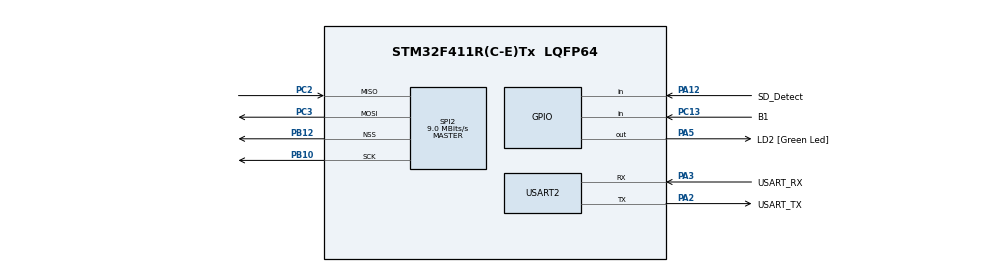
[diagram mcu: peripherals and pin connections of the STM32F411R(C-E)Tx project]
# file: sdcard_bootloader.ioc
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FATFS._CODE_PAGE=437
FATFS._FS_LOCK=0
FATFS._FS_MINIMIZE=0
FATFS._FS_READONLY=0
FATFS._MAX_SS=4096
FATFS._USE_FASTSEEK=0
FATFS._USE_LFN=1
FATFS._USE_MKFS=0
Mcu.Family=STM32F4
Mcu.Name=STM32F411R(C-E)Tx
Mcu.Package=LQFP64
NVIC.PriorityGroup=NVIC_PRIORITYGROUP_0
NVIC.USART2_IRQn=true\:0\:0\:false\:false\:true\:true\:true\:true
PA12.GPIO_Label=SD_Detect
PA12.Signal=GPIO_Input
PA13.GPIO_Label=TMS
PA13.Mode=Serial_Wire
PA13.Signal=SYS_JTMS-SWDIO
PA14.GPIO_Label=TCK
PA14.Mode=Serial_Wire
PA14.Signal=SYS_JTCK-SWCLK
PA2.GPIO_Label=USART_TX
PA2.Mode=Asynchronous
PA2.Signal=USART2_TX
PA3.GPIO_Label=USART_RX
PA3.Mode=Asynchronous
PA3.Signal=USART2_RX
PA5.GPIO_Label=LD2 [Green Led]
PA5.Signal=GPIO_Output
PB10.Mode=Full_Duplex_Master
PB10.Signal=SPI2_SCK
PB12.Mode=NSS_Signal_Hard_Output
PB12.Signal=SPI2_NSS
PB3.GPIO_Label=SWO
PB3.Signal=SYS_JTDO-SWO
PC13-ANTI_TAMP.GPIO_Label=B1
PC13-ANTI_TAMP.Signal=GPIO_Input
PC14-OSC32_IN.Mode=LSE-External-Oscillator
PC14-OSC32_IN.Signal=RCC_OSC32_IN
PC15-OSC32_OUT.Mode=LSE-External-Oscillator
PC15-OSC32_OUT.Signal=RCC_OSC32_OUT
PC2.Mode=Full_Duplex_Master
PC2.Signal=SPI2_MISO
PC3.Mode=Full_Duplex_Master
PC3.Signal=SPI2_MOSI
PC8.Signal=SDIO_D0
PD2.Signal=SDIO_CMD
PH0\ -\ OSC_IN.Mode=HSE-External-Clock-Source
PH0\ -\ OSC_IN.Signal=RCC_OSC_IN
PH1\ -\ OSC_OUT.Mode=HSE-External-Clock-Source
PH1\ -\ OSC_OUT.Signal=RCC_OSC_OUT
ProjectManager.HeapSize=0x200
ProjectManager.StackSize=0x400
ProjectManager.TargetToolchain=STM32CubeIDE
RCC.48MHZClocksFreq_Value=36000000
RCC.AHBFreq_Value=72000000
RCC.APB1CLKDivider=RCC_HCLK_DIV2
RCC.APB1Freq_Value=36000000
RCC.APB1TimFreq_Value=72000000
RCC.APB2Freq_Value=72000000
RCC.APB2TimFreq_Value=72000000
RCC.CortexFreq_Value=72000000
RCC.FLatency-AdvancedSettings=FLASH_LATENCY_2
RCC.HCLKFreq_Value=72000000
RCC.HSE_VALUE=8000000
RCC.HSI_VALUE=16000000
RCC.PLLM=8
RCC.PLLN=72
RCC.SYSCLKFreq_VALUE=72000000
RCC.SYSCLKSource=RCC_SYSCLKSOURCE_PLLCLK
RCC.VCOOutputFreq_Value=144000000
SPI2.BaudRatePrescaler=SPI_BAUDRATEPRESCALER_4
SPI2.CalculateBaudRate=9.0 MBits/s
SPI2.Direction=SPI_DIRECTION_2LINES
SPI2.Mode=SPI_MODE_MASTER
SPI2.VirtualNSS=VM_NSSHARD
SPI2.VirtualType=VM_MASTER
USART2.VirtualMode=VM_ASYNC
VP_FATFS_VS_Generic.Mode=User_defined
board=NUCLEO-F411RE

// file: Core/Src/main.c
/* USER CODE BEGIN Header */
/**
  ******************************************************************************
  * @file           : main.c
  * @brief          : Main program body
  ******************************************************************************
  * @attention
  *
  * Copyright (c) 2022 STMicroelectronics.
  * All rights reserved.
  *
  * This software is licensed under terms that can be found in the LICENSE file
  * in the root directory of this software component.
  * If no LICENSE file comes with this software, it is provided AS-IS.
  *
  ******************************************************************************
  */
/* USER CODE END Header */
#include "main.h"
#include "bootloader.h"

void SystemClock_Config(void);
static void MX_GPIO_Init(void);
static void MX_USART2_UART_Init(void);
static void MX_SPI2_Init(void);

int main(void)
{

  /* MCU Configuration--------------------------------------------------------*/

  /* Reset of all peripherals, Initializes the Flash interface and the Systick. */
  HAL_Init();

  /* Configure the system clock */
  SystemClock_Config();

  /* Initialize all configured peripherals */
  MX_GPIO_Init();
  MX_USART2_UART_Init();
  MX_FATFS_Init();
  MX_SPI2_Init();
  /* USER CODE BEGIN 2 */
  bootloader_mainloop();

  /* USER CODE END 2 */

  /* Infinite loop */
  while (1)
  {

  }
}

void SystemClock_Config(void)
{
  LL_FLASH_SetLatency(LL_FLASH_LATENCY_2);
  while(LL_FLASH_GetLatency()!= LL_FLASH_LATENCY_2)
  {
  }
  LL_PWR_SetRegulVoltageScaling(LL_PWR_REGU_VOLTAGE_SCALE1);
  LL_RCC_HSI_SetCalibTrimming(16);
  LL_RCC_HSI_Enable();

   /* Wait till HSI is ready */
  while(LL_RCC_HSI_IsReady() != 1)
  {

  }
  LL_RCC_PLL_ConfigDomain_SYS(LL_RCC_PLLSOURCE_HSI, LL_RCC_PLLM_DIV_8, 72, LL_RCC_PLLP_DIV_2);
  LL_RCC_PLL_Enable();

   /* Wait till PLL is ready */
  while(LL_RCC_PLL_IsReady() != 1)
  {

  }
  LL_RCC_SetAHBPrescaler(LL_RCC_SYSCLK_DIV_1);
  LL_RCC_SetAPB1Prescaler(LL_RCC_APB1_DIV_2);
  LL_RCC_SetAPB2Prescaler(LL_RCC_APB2_DIV_1);
  LL_RCC_SetSysClkSource(LL_RCC_SYS_CLKSOURCE_PLL);

   /* Wait till System clock is ready */
  while(LL_RCC_GetSysClkSource() != LL_RCC_SYS_CLKSOURCE_STATUS_PLL)
  {

  }
  LL_SetSystemCoreClock(72000000);

   /* Update the time base */
  if (HAL_InitTick (TICK_INT_PRIORITY) != HAL_OK)
  {
    Error_Handler();
  }
  LL_RCC_SetTIMPrescaler(LL_RCC_TIM_PRESCALER_TWICE);
}

static void MX_SPI2_Init(void)
{

  LL_SPI_InitTypeDef SPI_InitStruct = {0};

  LL_GPIO_InitTypeDef GPIO_InitStruct = {0};

  /* Peripheral clock enable */
  LL_APB1_GRP1_EnableClock(LL_APB1_GRP1_PERIPH_SPI2);

  LL_AHB1_GRP1_EnableClock(LL_AHB1_GRP1_PERIPH_GPIOC);
  LL_AHB1_GRP1_EnableClock(LL_AHB1_GRP1_PERIPH_GPIOB);
  /**SPI2 GPIO Configuration
  PC2   ------> SPI2_MISO
  PC3   ------> SPI2_MOSI
  PB10   ------> SPI2_SCK
  PB12   ------> SPI2_NSS
  */
  GPIO_InitStruct.Pin = LL_GPIO_PIN_2|LL_GPIO_PIN_3;
  GPIO_InitStruct.Mode = LL_GPIO_MODE_ALTERNATE;
  GPIO_InitStruct.Speed = LL_GPIO_SPEED_FREQ_VERY_HIGH;
  GPIO_InitStruct.OutputType = LL_GPIO_OUTPUT_PUSHPULL;
  GPIO_InitStruct.Pull = LL_GPIO_PULL_NO;
  GPIO_InitStruct.Alternate = LL_GPIO_AF_5;
  LL_GPIO_Init(GPIOC, &GPIO_InitStruct);

  GPIO_InitStruct.Pin = LL_GPIO_PIN_10|LL_GPIO_PIN_12;
  GPIO_InitStruct.Mode = LL_GPIO_MODE_ALTERNATE;
  GPIO_InitStruct.Speed = LL_GPIO_SPEED_FREQ_VERY_HIGH;
  GPIO_InitStruct.OutputType = LL_GPIO_OUTPUT_PUSHPULL;
  GPIO_InitStruct.Pull = LL_GPIO_PULL_NO;
  GPIO_InitStruct.Alternate = LL_GPIO_AF_5;
  LL_GPIO_Init(GPIOB, &GPIO_InitStruct);

  /* SPI2 parameter configuration*/
  SPI_InitStruct.TransferDirection = LL_SPI_FULL_DUPLEX;
  SPI_InitStruct.Mode = LL_SPI_MODE_MASTER;
  SPI_InitStruct.DataWidth = LL_SPI_DATAWIDTH_8BIT;
  SPI_InitStruct.ClockPolarity = LL_SPI_POLARITY_LOW;
  SPI_InitStruct.ClockPhase = LL_SPI_PHASE_1EDGE;
  SPI_InitStruct.NSS = LL_SPI_NSS_HARD_OUTPUT;
  SPI_InitStruct.BaudRate = LL_SPI_BAUDRATEPRESCALER_DIV4;
  SPI_InitStruct.BitOrder = LL_SPI_MSB_FIRST;
  SPI_InitStruct.CRCCalculation = LL_SPI_CRCCALCULATION_DISABLE;
  SPI_InitStruct.CRCPoly = 10;
  LL_SPI_Init(SPI2, &SPI_InitStruct);
  LL_SPI_SetStandard(SPI2, LL_SPI_PROTOCOL_MOTOROLA);

}

static void MX_USART2_UART_Init(void)
{

  LL_USART_InitTypeDef USART_InitStruct = {0};

  LL_GPIO_InitTypeDef GPIO_InitStruct = {0};

  /* Peripheral clock enable */
  LL_APB1_GRP1_EnableClock(LL_APB1_GRP1_PERIPH_USART2);

  LL_AHB1_GRP1_EnableClock(LL_AHB1_GRP1_PERIPH_GPIOA);
  /**USART2 GPIO Configuration
  PA2   ------> USART2_TX
  PA3   ------> USART2_RX
  */
  GPIO_InitStruct.Pin = USART_TX_Pin|USART_RX_Pin;
  GPIO_InitStruct.Mode = LL_GPIO_MODE_ALTERNATE;
  GPIO_InitStruct.Speed = LL_GPIO_SPEED_FREQ_VERY_HIGH;
  GPIO_InitStruct.OutputType = LL_GPIO_OUTPUT_PUSHPULL;
  GPIO_InitStruct.Pull = LL_GPIO_PULL_NO;
  GPIO_InitStruct.Alternate = LL_GPIO_AF_7;
  LL_GPIO_Init(GPIOA, &GPIO_InitStruct);
  USART_InitStruct.BaudRate = 115200;
  USART_InitStruct.DataWidth = LL_USART_DATAWIDTH_8B;
  USART_InitStruct.StopBits = LL_USART_STOPBITS_1;
  USART_InitStruct.Parity = LL_USART_PARITY_NONE;
  USART_InitStruct.TransferDirection = LL_USART_DIRECTION_TX;
  USART_InitStruct.HardwareFlowControl = LL_USART_HWCONTROL_NONE;
  USART_InitStruct.OverSampling = LL_USART_OVERSAMPLING_16;
  LL_USART_Init(USART2, &USART_InitStruct);
  LL_USART_ConfigAsyncMode(USART2);
  LL_USART_Enable(USART2);

}

static void MX_GPIO_Init(void)
{
  LL_GPIO_InitTypeDef GPIO_InitStruct = {0};

  /* GPIO Ports Clock Enable */
  LL_AHB1_GRP1_EnableClock(LL_AHB1_GRP1_PERIPH_GPIOC);
  LL_AHB1_GRP1_EnableClock(LL_AHB1_GRP1_PERIPH_GPIOH);
  LL_AHB1_GRP1_EnableClock(LL_AHB1_GRP1_PERIPH_GPIOA);
  LL_AHB1_GRP1_EnableClock(LL_AHB1_GRP1_PERIPH_GPIOB);
  LL_AHB1_GRP1_EnableClock(LL_AHB1_GRP1_PERIPH_GPIOD);

  /**/
  LL_GPIO_ResetOutputPin(LD2_GPIO_Port, LD2_Pin);

  /**/
  GPIO_InitStruct.Pin = B1_Pin;
  GPIO_InitStruct.Mode = LL_GPIO_MODE_INPUT;
  GPIO_InitStruct.Pull = LL_GPIO_PULL_NO;
  LL_GPIO_Init(B1_GPIO_Port, &GPIO_InitStruct);

  /**/
  GPIO_InitStruct.Pin = LD2_Pin;
  GPIO_InitStruct.Mode = LL_GPIO_MODE_OUTPUT;
  GPIO_InitStruct.Speed = LL_GPIO_SPEED_FREQ_LOW;
  GPIO_InitStruct.OutputType = LL_GPIO_OUTPUT_PUSHPULL;
  GPIO_InitStruct.Pull = LL_GPIO_PULL_NO;
  LL_GPIO_Init(LD2_GPIO_Port, &GPIO_InitStruct);

  /**/
  GPIO_InitStruct.Pin = LL_GPIO_PIN_8;
  GPIO_InitStruct.Mode = LL_GPIO_MODE_ALTERNATE;
  GPIO_InitStruct.Speed = LL_GPIO_SPEED_FREQ_VERY_HIGH;
  GPIO_InitStruct.OutputType = LL_GPIO_OUTPUT_PUSHPULL;
  GPIO_InitStruct.Pull = LL_GPIO_PULL_NO;
  GPIO_InitStruct.Alternate = LL_GPIO_AF_12;
  LL_GPIO_Init(GPIOC, &GPIO_InitStruct);

  /**/
  GPIO_InitStruct.Pin = SD_Detect_Pin;
  GPIO_InitStruct.Mode = LL_GPIO_MODE_INPUT;
  GPIO_InitStruct.Pull = LL_GPIO_PULL_NO;
  LL_GPIO_Init(SD_Detect_GPIO_Port, &GPIO_InitStruct);

  /**/
  GPIO_InitStruct.Pin = LL_GPIO_PIN_2;
  GPIO_InitStruct.Mode = LL_GPIO_MODE_ALTERNATE;
  GPIO_InitStruct.Speed = LL_GPIO_SPEED_FREQ_VERY_HIGH;
  GPIO_InitStruct.OutputType = LL_GPIO_OUTPUT_PUSHPULL;
  GPIO_InitStruct.Pull = LL_GPIO_PULL_NO;
  GPIO_InitStruct.Alternate = LL_GPIO_AF_12;
  LL_GPIO_Init(GPIOD, &GPIO_InitStruct);

}

void Error_Handler(void)
{
  __disable_irq();
  while (1)
  {
  }
}
